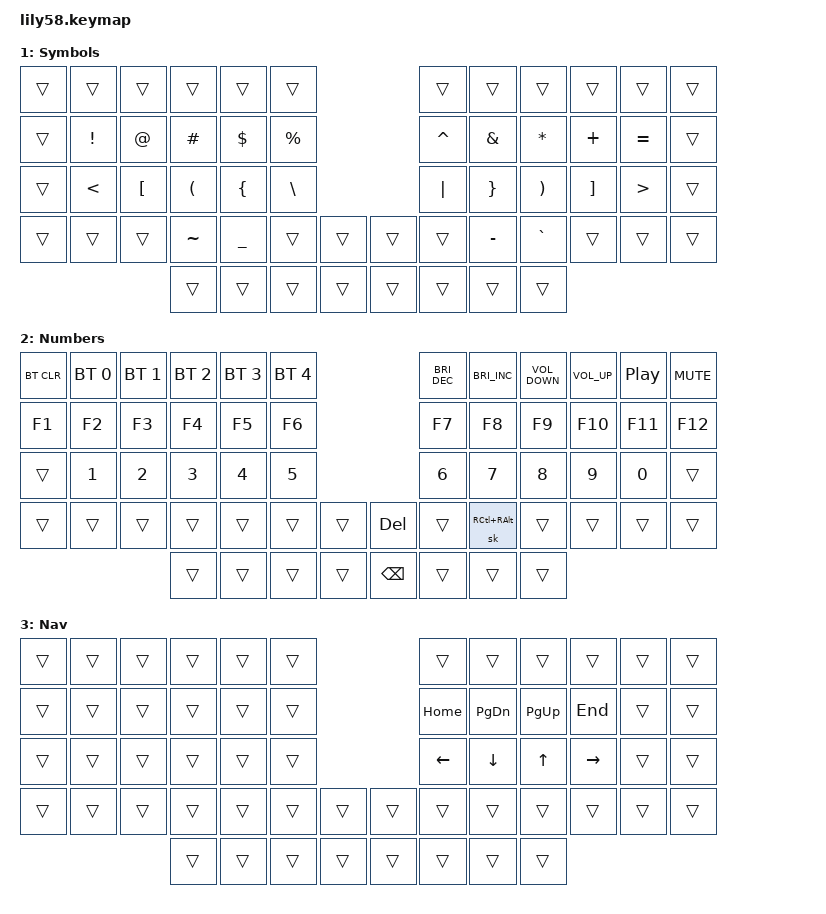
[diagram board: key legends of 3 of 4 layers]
/*
 * Copyright (c) 2020 The ZMK Contributors
 *
 * SPDX-License-Identifier: MIT
 */

#include <behaviors.dtsi>
#include <dt-bindings/zmk/bt.h>
#include <dt-bindings/zmk/keys.h>
#include "homerow_mods.dtsi"

/ {
    conditional_layers {
        compatible = "zmk,conditional-layers";

        tri_layer {
            if-layers = <1 2>;
            then-layer = <3>;
        };
    };

    behaviors {
        lt_thumb: layer_tap_thumb {
            compatible = "zmk,behavior-hold-tap";
            label = "LAYER_TAP_THUMB";
            #binding-cells = <2>;
            tapping-term-ms = <200>;
            quick-tap-ms = <0>;
            flavor = "balanced";
            bindings = <&mo>, <&kp>;
        };
    };

    keymap {
        compatible = "zmk,keymap";

        default_layer {
            display-name = "Base";
            bindings = <
&cw         &kp N1  &kp N2  &kp N3     &kp N4     &kp N5                         &kp N6  &kp N7    &kp N8     &kp N9   &kp N0    &kp GRAVE
&kp TAB     &kp Q   &kp W   &kp E      &kp R      &kp T                          &kp Y   &kp U     &kp I      &kp O    &kp P     &kp MINUS
&kp ESC     HRM_LEFT                                                        &kp G                          &kp H   HRM_RIGHT                                      &kp SQT
&kp LSHFT   &kp Z   &kp X   &kp C      &kp V      &kp B   &kp LCTRL     &kp RGUI  &kp N   &kp M     &kp COMMA  &kp DOT  &kp FSLH  &kp RSHFT
                            &kp LSHFT  &kp LCTRL  &lt_thumb 2 BSPC   &kp SPACE    &kp RET   &lt_thumb 1 TAB   &kp RGUI  &kp RSHFT
            >;

            sensor-bindings = <&inc_dec_kp C_VOL_UP C_VOL_DN>;
        };

        symbols {
            display-name = "Symbols";
            bindings = <
&trans  &trans           &trans            &trans                &trans          &trans                         &trans     &trans           &trans                 &trans             &trans            &trans
&trans  &kp EXCLAMATION  &kp AT_SIGN       &kp POUND             &kp DOLLAR      &kp PERCENT                    &kp CARET  &kp AMPERSAND    &kp ASTERISK           &kp PLUS           &kp EQUAL         &trans
&trans  &kp LESS_THAN    &kp LEFT_BRACKET  &kp LEFT_PARENTHESIS  &kp LEFT_BRACE  &kp BSLH                       &kp PIPE   &kp RIGHT_BRACE  &kp RIGHT_PARENTHESIS  &kp RIGHT_BRACKET  &kp GREATER_THAN  &trans
&trans  &trans           &trans            &kp TILDE             &kp UNDERSCORE  &trans       &trans    &trans  &trans     &kp MINUS        &kp GRAVE              &trans             &trans            &trans
                                           &trans                &trans          &trans       &trans    &trans  &trans     &trans           &trans
            >;
        };

        numbers {
            display-name = "Numbers";
            bindings = <
&bt BT_CLR  &bt BT_SEL 0  &bt BT_SEL 1  &bt BT_SEL 2  &bt BT_SEL 3  &bt BT_SEL 4                      &kp C_BRIGHTNESS_DEC  &kp C_BRIGHTNESS_INC  &kp C_VOLUME_DOWN  &kp C_VOLUME_UP  &kp C_PLAY_PAUSE  &kp C_MUTE
&kp F1      &kp F2        &kp F3        &kp F4        &kp F5        &kp F6                            &kp F7                &kp F8                &kp F9             &kp F10          &kp F11           &kp F12
&trans      &kp NUMBER_1  &kp NUMBER_2  &kp NUMBER_3  &kp NUMBER_4  &kp NUMBER_5                      &kp NUMBER_6          &kp NUMBER_7          &kp NUMBER_8       &kp NUMBER_9     &kp NUMBER_0      &trans
&trans      &trans        &trans        &trans        &trans        &trans        &trans    &kp DEL   &trans                &sk RC(RALT)          &trans             &trans           &trans            &trans
                                        &trans        &trans        &trans        &trans    &kp BSPC  &trans                &trans                &trans
            >;
        };

        navigation {
            display-name = "Nav";
            bindings = <
&trans  &trans  &trans  &trans  &trans  &trans                    &trans    &trans         &trans       &trans     &trans  &trans
&trans  &trans  &trans  &trans  &trans  &trans                    &kp HOME  &kp PAGE_DOWN  &kp PAGE_UP  &kp END    &trans  &trans
&trans  &trans  &trans  &trans  &trans  &trans                    &kp LEFT  &kp DOWN       &kp UP       &kp RIGHT  &trans  &trans
&trans  &trans  &trans  &trans  &trans  &trans  &trans    &trans  &trans    &trans         &trans       &trans     &trans  &trans
                        &trans  &trans  &trans  &trans    &trans  &trans    &trans         &trans
            >;
        };
    };
};
